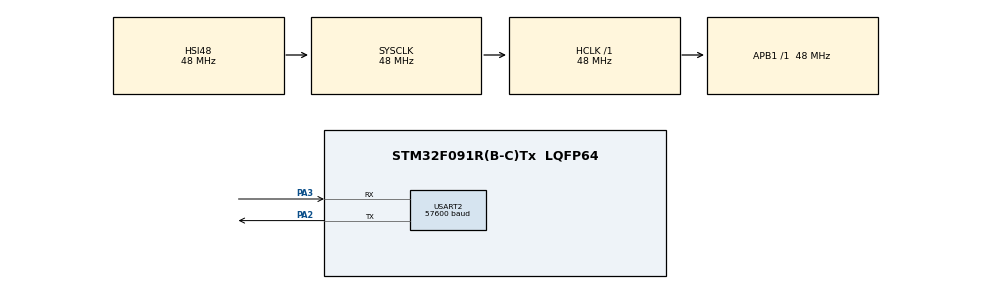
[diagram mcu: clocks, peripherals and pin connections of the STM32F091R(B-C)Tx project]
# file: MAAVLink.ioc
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Mcu.Family=STM32F0
Mcu.Name=STM32F091R(B-C)Tx
Mcu.Package=LQFP64
PA2.Mode=Asynchronous
PA2.Signal=USART2_TX
PA3.Mode=Asynchronous
PA3.Signal=USART2_RX
ProjectManager.HeapSize=0x200
ProjectManager.StackSize=0x400
ProjectManager.TargetToolchain=STM32CubeIDE
RCC.AHBFreq_Value=48000000
RCC.APB1Freq_Value=48000000
RCC.APB1TimFreq_Value=48000000
RCC.FLatency-AdvancedSettings=FLASH_LATENCY_1
RCC.HCLKFreq_Value=48000000
RCC.PLLDivider=RCC_PREDIV_DIV2
RCC.PLLMUL=RCC_PLL_MUL12
RCC.PREFETCH_ENABLE-AdvancedSettings=1
RCC.SYSCLKFreq_VALUE=48000000
RCC.SYSCLKSource=RCC_SYSCLKSOURCE_HSI48
USART2.BaudRate=57600
USART2.VirtualMode-Asynchronous=VM_ASYNC
board=NUCLEO-F091RC

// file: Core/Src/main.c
/* USER CODE BEGIN Header */
/**
  ******************************************************************************
  * @file           : main.c
  * @brief          : Main program body
  ******************************************************************************
  * @attention
  *
  * Copyright (c) 2023 STMicroelectronics.
  * All rights reserved.
  *
  * This software is licensed under terms that can be found in the LICENSE file
  * in the root directory of this software component.
  * If no LICENSE file comes with this software, it is provided AS-IS.
  *
  ******************************************************************************
  */
/* USER CODE END Header */
#include "main.h"

/* USER CODE BEGIN Includes */
#include "mavlink.h"
/* USER CODE END Includes */

/* USER CODE BEGIN PD */
#define MAX_STREAMS 2
/* USER CODE END PD */

UART_HandleTypeDef huart2;

/* USER CODE BEGIN PV */
const uint8_t systemID = 1;
const uint8_t componentID = 1;
mavlink_status_t status;
mavlink_message_t msg;
int chan = MAVLINK_COMM_0; //use channel 0 only if 1 communication channel used
mavlink_system_t mavlink_system = {
systemID,
componentID
};
/* USER CODE END PV */

void SystemClock_Config(void);
static void MX_GPIO_Init(void);
static void MX_USART2_UART_Init(void);

int main(void)
{
  /* USER CODE BEGIN 1 */
//define system type
uint8_t system_type = MAV_TYPE_GENERIC;
  /* USER CODE END 1 */

  /* MCU Configuration--------------------------------------------------------*/

  /* Reset of all peripherals, Initializes the Flash interface and the Systick. */
  HAL_Init();

  /* Configure the system clock */
  SystemClock_Config();

  /* Initialize all configured peripherals */
  MX_GPIO_Init();
  MX_USART2_UART_Init();

  /* Infinite loop */
  while (1)
  {

    /* USER CODE BEGIN 3 */
	  comm_receive();
  }
  /* USER CODE END 3 */
}

void SystemClock_Config(void)
{
  RCC_OscInitTypeDef RCC_OscInitStruct = {0};
  RCC_ClkInitTypeDef RCC_ClkInitStruct = {0};
  RCC_PeriphCLKInitTypeDef PeriphClkInit = {0};

  /** Initializes the RCC Oscillators according to the specified parameters
  * in the RCC_OscInitTypeDef structure.
  */
  RCC_OscInitStruct.OscillatorType = RCC_OSCILLATORTYPE_HSI48;
  RCC_OscInitStruct.HSI48State = RCC_HSI48_ON;
  RCC_OscInitStruct.PLL.PLLState = RCC_PLL_NONE;
  if (HAL_RCC_OscConfig(&RCC_OscInitStruct) != HAL_OK)
  {
    Error_Handler();
  }

  /** Initializes the CPU, AHB and APB buses clocks
  */
  RCC_ClkInitStruct.ClockType = RCC_CLOCKTYPE_HCLK|RCC_CLOCKTYPE_SYSCLK
                              |RCC_CLOCKTYPE_PCLK1;
  RCC_ClkInitStruct.SYSCLKSource = RCC_SYSCLKSOURCE_HSI48;
  RCC_ClkInitStruct.AHBCLKDivider = RCC_SYSCLK_DIV1;
  RCC_ClkInitStruct.APB1CLKDivider = RCC_HCLK_DIV1;

  if (HAL_RCC_ClockConfig(&RCC_ClkInitStruct, FLASH_LATENCY_1) != HAL_OK)
  {
    Error_Handler();
  }
  PeriphClkInit.PeriphClockSelection = RCC_PERIPHCLK_USART2;
  PeriphClkInit.Usart2ClockSelection = RCC_USART2CLKSOURCE_PCLK1;
  if (HAL_RCCEx_PeriphCLKConfig(&PeriphClkInit) != HAL_OK)
  {
    Error_Handler();
  }
}

static void MX_USART2_UART_Init(void)
{

  huart2.Instance = USART2;
  huart2.Init.BaudRate = 57600;
  huart2.Init.WordLength = UART_WORDLENGTH_8B;
  huart2.Init.StopBits = UART_STOPBITS_1;
  huart2.Init.Parity = UART_PARITY_NONE;
  huart2.Init.Mode = UART_MODE_TX_RX;
  huart2.Init.HwFlowCtl = UART_HWCONTROL_NONE;
  huart2.Init.OverSampling = UART_OVERSAMPLING_16;
  huart2.Init.OneBitSampling = UART_ONE_BIT_SAMPLE_DISABLE;
  huart2.AdvancedInit.AdvFeatureInit = UART_ADVFEATURE_NO_INIT;
  if (HAL_UART_Init(&huart2) != HAL_OK)
  {
    Error_Handler();
  }

}

static void MX_GPIO_Init(void)
{

  /* GPIO Ports Clock Enable */
  __HAL_RCC_GPIOA_CLK_ENABLE();

}

/* USER CODE BEGIN 4 */

void Mav_Request_Data() {
mavlink_message_t msg;
uint8_t buf[MAVLINK_MAX_PACKET_LEN];

// STREAMS that can be requested
 /*
  * Definitions are in common.h: enum MAV_DATA_STREAM
  *
  * MAV_DATA_STREAM_ALL=0, // Enable all data streams
  * MAV_DATA_STREAM_RAW_SENSORS=1, /* Enable IMU_RAW, GPS_RAW, GPS_STATUS packets.
  * MAV_DATA_STREAM_EXTENDED_STATUS=2, /* Enable GPS_STATUS, CONTROL_STATUS, AUX_STATUS
  * MAV_DATA_STREAM_RC_CHANNELS=3, /* Enable RC_CHANNELS_SCALED, RC_CHANNELS_RAW, SERVO_OUTPUT_RAW
  * MAV_DATA_STREAM_RAW_CONTROLLER=4, /* Enable ATTITUDE_CONTROLLER_OUTPUT, POSITION_CONTROLLER_OUTPUT, NAV_CONTROLLER_OUTPUT.
  * MAV_DATA_STREAM_POSITION=6, /* Enable LOCAL_POSITION, GLOBAL_POSITION/GLOBAL_POSITION_INT messages.
  * MAV_DATA_STREAM_EXTRA1=10, /* Dependent on the autopilot
  * MAV_DATA_STREAM_EXTRA2=11, /* Dependent on the autopilot
  * MAV_DATA_STREAM_EXTRA3=12, /* Dependent on the autopilot
  * MAV_DATA_STREAM_ENUM_END=13,
  *
  * Data in PixHawk available in:
  *  - Battery, amperage and voltage (SYS_STATUS) in MAV_DATA_STREAM_EXTENDED_STATUS
  *  - Gyro info (IMU_SCALED) in MAV_DATA_STREAM_EXTRA1
  */

 // To be setup according to the needed information to be requested from the Pixhawk
 //const int  maxStreams = 2;
 const uint8_t MAVStreams[MAX_STREAMS] = {MAV_DATA_STREAM_EXTENDED_STATUS, MAV_DATA_STREAM_EXTRA1};
 const uint16_t MAVRates[MAX_STREAMS] = {0x02,0x05};

 for (int i=0; i < MAX_STREAMS; i++) {
   /*
    * mavlink_msg_request_data_stream_pack(system_id, component_id,
    *    &msg,
    *    target_system, target_component,
    *    MAV_DATA_STREAM_POSITION, 10000000, 1);
    *
    * mavlink_msg_request_data_stream_pack(uint8_t system_id, uint8_t component_id,
    *    mavlink_message_t* msg,
    *    uint8_t target_system, uint8_t target_component, uint8_t req_stream_id,
    *    uint16_t req_message_rate, uint8_t start_stop)
    *
    */
   mavlink_msg_request_data_stream_pack(2, 200, &msg, 1, 0, MAVStreams[i], MAVRates[i], 1);
   uint16_t len = mavlink_msg_to_send_buffer(buf, &msg);
   //write output to UART
   HAL_UART_Transmit(&huart2, (uint16_t *)(&msg), sizeof(msg), HAL_MAX_DELAY);
 }
}
void comm_receive() {
  mavlink_message_t msg;
  mavlink_status_t status;

  while(HAL_UART_Receive(&huart2, (uint8_t *)(&status), 1, HAL_MAX_DELAY) == HAL_OK) {
    uint8_t c = HAL_UART_Receive(&huart2, (uint8_t *)(&msg), sizeof(msg), HAL_MAX_DELAY);

    // Try to get a new message
    if(mavlink_parse_char(MAVLINK_COMM_0, c, &msg, &status)) {

      // Handle message
      switch(msg.msgid) {
        case MAVLINK_MSG_ID_HEARTBEAT:  // #0: Heartbeat
          {
            // E.g. read GCS heartbeat and go into
            // comm lost mode if timer times out
        	  printf("Pixhawk 4 Heartbeat Received! \n\r");
          }
          break;

        case MAVLINK_MSG_ID_SYS_STATUS:  // #1: SYS_STATUS
          {
            /* Message decoding: PRIMITIVE
             *    mavlink_msg_sys_status_decode(const mavlink_message_t* msg, mavlink_sys_status_t* sys_status)
             */
            //mavlink_message_t* msg;
            mavlink_sys_status_t sys_status;
            mavlink_msg_sys_status_decode(&msg, &sys_status);
          }
          break;

        case MAVLINK_MSG_ID_PARAM_VALUE:  // #22: PARAM_VALUE
          {
            /* Message decoding: PRIMITIVE
             *    mavlink_msg_param_value_decode(const mavlink_message_t* msg, mavlink_param_value_t* param_value)
             */
            //mavlink_message_t* msg;
            mavlink_param_value_t param_value;
            mavlink_msg_param_value_decode(&msg, &param_value);
          }
          break;

        case MAVLINK_MSG_ID_RAW_IMU:  // #27: RAW_IMU
          {
            /* Message decoding: PRIMITIVE
             *    static inline void mavlink_msg_raw_imu_decode(const mavlink_message_t* msg, mavlink_raw_imu_t* raw_imu)
             */
            mavlink_raw_imu_t raw_imu;
            mavlink_msg_raw_imu_decode(&msg, &raw_imu);
          }
          break;

        case MAVLINK_MSG_ID_ATTITUDE:  // #30
          {
            /* Message decoding: PRIMITIVE
             *    mavlink_msg_attitude_decode(const mavlink_message_t* msg, mavlink_attitude_t* attitude)
             */
            mavlink_attitude_t attitude;
            mavlink_msg_attitude_decode(&msg, &attitude);
            char leds_modo = 0;
            if(attitude.roll>1) { leds_modo = 0; }
            else if(attitude.roll<-1) { leds_modo = 2; }
            else { leds_modo=1; }
          }
          break;
       default:
          break;
      }
    }
  }
}
/* USER CODE END 4 */

void Error_Handler(void)
{
  __disable_irq();
  while (1)
  {
  }
}
